# STC32G144K246 register map
Vendor: STC; File version: 2.0
Registers are 8-bit, read-write, no defined reset value unless marked. A register's access mark holds for its fields unless they carry their own. Offsets are from the block's base; [hi:lo] are bit positions.

## UART1 — USART1 收发、运行模式与超时
Base 0x007EFD71
0x00 UR1TOSR ro — 串口1接收超时状态寄存器
  [0] UR1TOIF — 串口1 超时中断请求标志位。标志位需要软件向UR1CTOIF 位写“1”清零
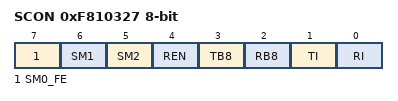
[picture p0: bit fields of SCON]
0xF810327 SCON — 串口1控制寄存器
  [7] SM0_FE — 当PCON寄存器中的SMOD0位为1时，该位为帧错误检测标志位。当串口在接收过程中检测到
  [6] SM1 — 尚未自动匹配到此字段的独立说明；请查看下方章节说明。
  [5] SM2 — 允许模式2 或模式3 多机通信控制位。当串口1 使用模式2 或模式3 时，如果SM2 位为1 且REN 位为1，则接收机处于地址帧筛选状态。此时可以利用接收到的第9 位（即RB8）来筛选地址帧， 若RB8=1，说明该帧是地址帧，地址信息可以进入SBUF，并使RI 为1，进而在中断服务程序中 再进行地
  [4] REN — 允许/禁止串口接收控制位
    0=禁止串口接收数据; 1=允许串口接收数据
  [3] TB8 — 当串口1 使用模式2 或模式3 时，TB8 为要发送的第9 位数据，按需要由软件置位或清0。在模 式0 和模式1 中，该位不用。
  [2] RB8 — 当串口1 使用模式2 或模式3 时，RB8 为接收到的第9 位数据，一般用作校验位或者地址帧/数据 帧标志位。在模式0 和模式1 中，该位不用。
  [1] TI — 串口1发送完成中断请求标志。需要软件清零。
  [0] RI — 串口1接收完成中断请求标志。需要软件清零。

## UART2 — USART2 收发、运行模式与超时
Base 0x007EFD75
0x00 UR2TOSR ro — 串口2接收超时状态寄存器
  [0] UR2TOIF — 串口2 超时中断请求标志位。标志位需要软件向UR2CTOIF 位写“1”清零
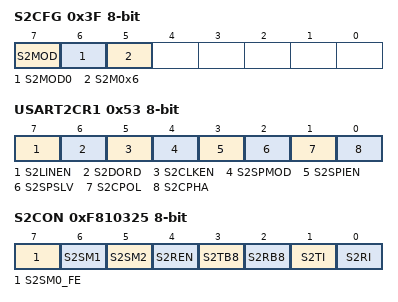
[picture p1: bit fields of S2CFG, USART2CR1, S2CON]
0x3F S2CFG — 串口2配置寄存器
  [7] S2MOD — 串口2 波特率控制位
    0=SYSclk波特率=𝟔𝟒; 1=SYSclk波特率=𝟑𝟐
  [6] S2MOD0 — 帧错误检测控制位
    0=无帧错检测功能; 1=使能帧错误检测功能。此时S2CON 的S2SM0/FE 为FE 功能，即为帧错误检测标志位。
  [5] S2M0x6 — 串口2 模式0 的通讯速度控制
0x53 USART2CR1 — 串口2控制寄存器1
  [7] S2LINEN — LIN 模式使能位
    0=禁止LIN 模式; 1=使能LIN 模式
  [6] S2DORD — SPI 模式数据位发送/接收的顺序
    0=先发送/接收数据的高位（MSB）; 1=先发送/接收数据的低位（LSB）
  [5] S2CLKEN — SmartCard 模式时钟输出控制位
    0=禁止时钟输出; 1=使能时钟输出
  [4] S2SPMOD — SPI 模式使能位
    0=禁止SPI 模式; 1=使能SPI 模式
  [3] S2SPIEN — SPI 使能位
    0=禁止SPI 功能; 1=使能SPI 功能
  [2] S2SPSLV — SPI 从机模式使能位
    0=SPI 为主机模式; 1=SPI 为从机模式
  [1] S2CPOL — SPI 时钟极性控制
    0=SCLK 空闲时为低电平，SCLK 的前时钟沿为上升沿，后时钟沿为下降沿; 1=SCLK 空闲时为高电平，SCLK 的前时钟沿为下降沿，后时钟沿为上升沿
  [0] S2CPHA — SPI 时钟相位控制
    0=数据SS 管脚为低电平驱动第一位数据并在SCLK 的后时钟沿改变数据，前时钟沿采样数据; 1=数据在SCLK 的前时钟沿驱动，后时钟沿采样
0xF810325 S2CON — 串口2控制寄存器
  [7] S2SM0_FE — 当S2CFG寄存器中的S2MOD0位为1时，该位为帧错误检测标志位。当串口2在接收过程中检
  [6] S2SM1 — 尚未自动匹配到此字段的独立说明；请查看下方章节说明。
  [5] S2SM2 — 允许模式2 或模式3 多机通信控制位。当串口2 使用模式2 或模式3 时，如果S2SM2 位为1 且 S2REN 位为1，则接收机处于地址帧筛选状态。此时可以利用接收到的第9 位（即S2RB8）来筛 选地址帧，若S2RB8=1，说明该帧是地址帧，地址信息可以进入S2BUF，并使S2RI 为1，进而
  [4] S2REN — 允许/禁止串口接收控制位
    0=禁止串口接收数据; 1=允许串口接收数据
  [3] S2TB8 — 当串口2 使用模式2 或模式3 时，S2TB8 为要发送的第9 位数据，按需要由软件置位或清0。 在模式0 和模式1 中，该位不用。
  [2] S2RB8 — 当串口2 使用模式2 或模式3 时，S2RB8 为接收到的第9 位数据，一般用作校验位或者地址帧 /数据帧标志位。在模式0 和模式1 中，该位不用。
  [1] S2TI — 串口2发送完成中断请求标志。需要软件清零。
  [0] S2RI — 串口2接收完成中断请求标志。需要软件清零。

## UART3 — USART3 收发、运行模式与超时
Base 0x007EFD79
0x00 UR3TOSR ro — 串口3接收超时状态寄存器
  [0] UR3TOIF — 串口3 超时中断请求标志位。标志位需要软件向UR3CTOIF 位写“1”清零
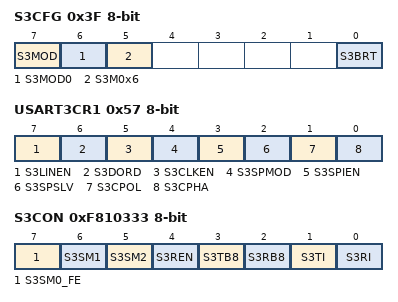
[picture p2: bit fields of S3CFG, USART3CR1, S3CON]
0x3F S3CFG — 串口3配置寄存器
  [7] S3MOD — 串口3 波特率控制位
    0=SYSclk波特率=𝟔𝟒; 1=SYSclk波特率=𝟑𝟐
  [6] S3MOD0 — 帧错误检测控制位
    0=无帧错检测功能; 1=使能帧错误检测功能。此时S3CON 的S3SM0/FE 为FE 功能，即为帧错误检测标志位。
  [5] S3M0x6 — 串口3 模式0 的通讯速度控制
    0=串口3 模式0 的波特率不加倍，固定为Fosc/12; 1=串口3 模式0 的波特率6 倍速，即固定为Fosc/12*6 ＝ Fosc/2
  [0] S3BRT — 串口3 波特率发生器选择位
    0=选择定时器2 作为波特率发生器（默认值）; 1=选择定时器3 作为波特率发生器
0x57 USART3CR1 — 串口3控制寄存器1
  [7] S3LINEN — LIN 模式使能位
    0=禁止LIN 模式; 1=使能LIN 模式
  [6] S3DORD — SPI 模式数据位发送/接收的顺序
    0=先发送/接收数据的高位（MSB）; 1=先发送/接收数据的低位（LSB）
  [5] S3CLKEN — SmartCard 模式时钟输出控制位
    0=禁止时钟输出; 1=使能时钟输出
  [4] S3SPMOD — SPI 模式使能位
    0=禁止SPI 模式; 1=使能SPI 模式
  [3] S3SPIEN — SPI 使能位
    0=禁止SPI 功能; 1=使能SPI 功能
  [2] S3SPSLV — SPI 从机模式使能位
    0=SPI 为主机模式; 1=SPI 为从机模式
  [1] S3CPOL — SPI 时钟极性控制
    0=SCLK 空闲时为低电平，SCLK 的前时钟沿为上升沿，后时钟沿为下降沿; 1=SCLK 空闲时为高电平，SCLK 的前时钟沿为下降沿，后时钟沿为上升沿
  [0] S3CPHA — SPI 时钟相位控制
    0=数据SS 管脚为低电平驱动第一位数据并在SCLK 的后时钟沿改变数据，前时钟沿采样数据; 1=数据在SCLK 的前时钟沿驱动，后时钟沿采样
0xF810333 S3CON — 串口3控制寄存器
  [7] S3SM0_FE — 当S3CFG寄存器中的S3MOD0位为1时，该位为帧错误检测标志位。当串口3在接收过程中检
  [6] S3SM1 — 尚未自动匹配到此字段的独立说明；请查看下方章节说明。
  [5] S3SM2 — 允许模式2 或模式3 多机通信控制位。当串口3 使用模式2 或模式3 时，如果S3SM2 位为1 且 S3REN 位为1，则接收机处于地址帧筛选状态。此时可以利用接收到的第9 位（即S3RB8）来筛 选地址帧，若S3RB8=1，说明该帧是地址帧，地址信息可以进入S3BUF，并使S3RI 为1，进而
  [4] S3REN — 允许/禁止串口接收控制位
    0=禁止串口接收数据; 1=允许串口接收数据
  [3] S3TB8 — 当串口3 使用模式2 或模式3 时，S3TB8 为要发送的第9 位数据，按需要由软件置位或清0。 在模式0 和模式1 中，该位不用。
  [2] S3RB8 — 当串口3 使用模式2 或模式3 时，S3RB8 为接收到的第9 位数据，一般用作校验位或者地址帧 /数据帧标志位。在模式0 和模式1 中，该位不用。
  [1] S3TI — 串口3发送完成中断请求标志。需要软件清零。
  [0] S3RI — 串口3接收完成中断请求标志。需要软件清零。
